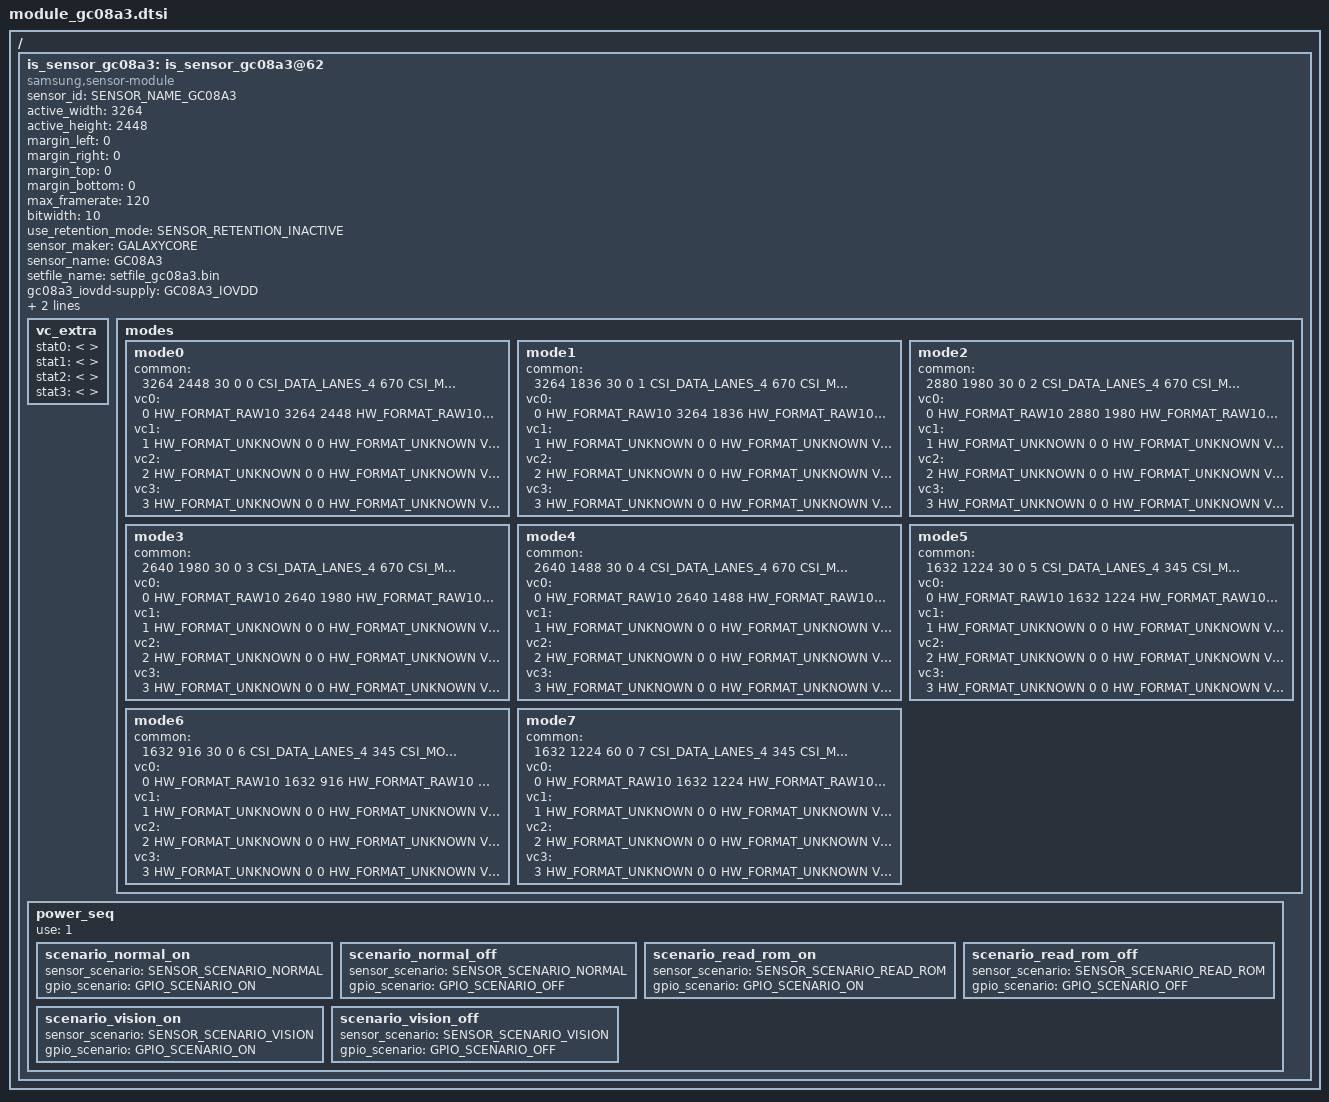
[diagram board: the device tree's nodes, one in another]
/*
 * SAMSUNG EXYNOSxxxx board camera device tree source
 *
 * Copyright (c) 2021 Samsung Electronics Co., Ltd.
 *        http://www.samsung.com
 *
 * This program is free software; you can redistribute it and/or modify
 * it under the terms of the GNU General Public License version 2 as
 * published by the Free Software Foundation.
 */

#include <dt-bindings/camera/exynos_is_dt.h>

#ifndef USE_VENDOR_PWR_PIN_NAME
#define GC08A3_IOVDD	<>
#define GC08A3_AVDD	<>
#define GC08A3_DVDD	<>
#endif

/ {
	fragment@camera {
		target-path = "/";
		__overlay__ {
			is_sensor_gc08a3: is_sensor_gc08a3@62 {
				compatible = "samsung,sensor-module";

				/* common */
				sensor_id = <SENSOR_NAME_GC08A3>;
				active_width = <3264>;
				active_height = <2448>;
				margin_left = <0>;
				margin_right = <0>;
				margin_top = <0>;
				margin_bottom = <0>;
				max_framerate = <120>;
				bitwidth = <10>;
				use_retention_mode = <SENSOR_RETENTION_INACTIVE>;
				sensor_maker = "GALAXYCORE";
				sensor_name = "GC08A3";
				setfile_name = "setfile_gc08a3.bin";

				gc08a3_iovdd-supply = GC08A3_IOVDD;
				gc08a3_avdd-supply = GC08A3_AVDD;
				gc08a3_dvdd-supply = GC08A3_DVDD;

				status = "okay";

				vc_extra {
					/* ex) statX = <stat_type, sensor_mode, max_width, max_height, max_element> */
					stat0 = </* not avaliable */>;	/* VC_BUF_DATA_TYPE_SENSOR_STAT1 */
					stat1 = </* not avaliable */>;	/* VC_BUF_DATA_TYPE_GENERAL_STAT1 */
					stat2 = </* not avaliable */>;	/* VC_BUF_DATA_TYPE_SENSOR_STAT2 */
					stat3 = </* not avaliable */>;	/* VC_BUF_DATA_TYPE_GENERAL_STAT2 */
				};

/*
 * [Mode Information]
 *
 * Reference File : GC08A3 MIPI data rate 897M official setfile V1.0.8.xlsx
 * Update Data    : 2021-10-26
 * Author         : g.lakshay
 *
 *  - Global setting
 *
 *  - Mode setting
 *  [ 0 ] 2576 x 1932(4:3)    @30,  MIPI lane: 2, MIPI data rate(Mbps/lane):  897, Mclk(Mhz): 26
 *  [ 1 ] 2560 x 1440(16:9)   @30,  MIPI lane: 2, MIPI data rate(Mbps/lane):  897, Mclk(Mhz): 26
 *  [ 2 ] 2224 x 1080(18.5:9) @30,  MIPI lane: 2, MIPI data rate(Mbps/lane):  897, Mclk(Mhz): 26
 *  [ 3 ] 2576 x 1188(19.5:9) @30,  MIPI lane: 2, MIPI data rate(Mbps/lane):  897, Mclk(Mhz): 26
 *  [ 4 ] 2576 x 1160(20:9)   @30,  MIPI lane: 2, MIPI data rate(Mbps/lane):  897, Mclk(Mhz): 26
 *  [ 5 ] 1920 x 1920(1:1)    @30,  MIPI lane: 2, MIPI data rate(Mbps/lane):  897, Mclk(Mhz): 26
 *  [ 6 ] 1280 x 960(4:3)     @30,  MIPI lane: 2, MIPI data rate(Mbps/lane):  897, Mclk(Mhz): 26
 *  [ 7 ] 1280 x 720(16:9)    @30,  MIPI lane: 2, MIPI data rate(Mbps/lane):  897, Mclk(Mhz): 26
 *  [ 8 ] 800 x 600(4:3)      @60,  MIPI lane: 2, MIPI data rate(Mbps/lane):  897, Mclk(Mhz): 26
 *  [ 9 ] 640 x 480(4:3)      @120,  MIPI lane: 2, MIPI data rate(Mbps/lane):  448, Mclk(Mhz): 26
 *
 */

				/* sensor modes */
				modes {
						/* common = <width, height, fps, settle, mode, lane, speed, interleave, lrte, pd_mode> */
						/* vcX = <map, hwformat, width, height, hwformat, type, width, height> */

					/* 0 : 3264x2448@30fps 4:3 */
					mode0 {
						common = <3264 2448 30 0 0 CSI_DATA_LANES_4 670 CSI_MODE_VC_ONLY LRTE_DISABLE PD_NONE EX_NONE>;
						vc0 = </* in */ 0 HW_FORMAT_RAW10 3264 2448	/* out */ HW_FORMAT_RAW10 VC_NOTHING 3264 2448>;
						vc1 = </* in */ 1 HW_FORMAT_UNKNOWN 0 0		/* out */ HW_FORMAT_UNKNOWN VC_NOTHING 0 0>;
						vc2 = </* in */ 2 HW_FORMAT_UNKNOWN 0 0		/* out */ HW_FORMAT_UNKNOWN VC_NOTHING 0 0>;
						vc3 = </* in */ 3 HW_FORMAT_UNKNOWN 0 0		/* out */ HW_FORMAT_UNKNOWN VC_NOTHING 0 0>;
					};
					/* 1 : 3264x1836@30fps 16:9 */
					mode1 {
						common = <3264 1836 30 0 1 CSI_DATA_LANES_4 670 CSI_MODE_VC_ONLY LRTE_DISABLE PD_NONE EX_NONE>;
						vc0 = </* in */ 0 HW_FORMAT_RAW10 3264 1836	/* out */ HW_FORMAT_RAW10 VC_NOTHING 3264 1836>;
						vc1 = </* in */ 1 HW_FORMAT_UNKNOWN 0 0		/* out */ HW_FORMAT_UNKNOWN VC_NOTHING 0 0>;
						vc2 = </* in */ 2 HW_FORMAT_UNKNOWN 0 0		/* out */ HW_FORMAT_UNKNOWN VC_NOTHING 0 0>;
						vc3 = </* in */ 3 HW_FORMAT_UNKNOWN 0 0		/* out */ HW_FORMAT_UNKNOWN VC_NOTHING 0 0>;
					};
					/* 2 : 2880x1980@30fps 16:9 */
					mode2 {
						common = <2880 1980 30 0 2 CSI_DATA_LANES_4 670 CSI_MODE_VC_ONLY LRTE_DISABLE PD_NONE EX_NONE>;
						vc0 = </* in */ 0 HW_FORMAT_RAW10 2880 1980	/* out */ HW_FORMAT_RAW10 VC_NOTHING 2880 1980>;
						vc1 = </* in */ 1 HW_FORMAT_UNKNOWN 0 0		/* out */ HW_FORMAT_UNKNOWN VC_NOTHING 0 0>;
						vc2 = </* in */ 2 HW_FORMAT_UNKNOWN 0 0		/* out */ HW_FORMAT_UNKNOWN VC_NOTHING 0 0>;
						vc3 = </* in */ 3 HW_FORMAT_UNKNOWN 0 0		/* out */ HW_FORMAT_UNKNOWN VC_NOTHING 0 0>;
					};
					/* 3 : 2640x1980@30fps 4:3 */
					mode3 {
						common = <2640 1980 30 0 3 CSI_DATA_LANES_4 670 CSI_MODE_VC_ONLY LRTE_DISABLE PD_NONE EX_NONE>;
						vc0 = </* in */ 0 HW_FORMAT_RAW10 2640 1980	/* out */ HW_FORMAT_RAW10 VC_NOTHING 2640 1980>;
						vc1 = </* in */ 1 HW_FORMAT_UNKNOWN 0 0		/* out */ HW_FORMAT_UNKNOWN VC_NOTHING 0 0>;
						vc2 = </* in */ 2 HW_FORMAT_UNKNOWN 0 0		/* out */ HW_FORMAT_UNKNOWN VC_NOTHING 0 0>;
						vc3 = </* in */ 3 HW_FORMAT_UNKNOWN 0 0		/* out */ HW_FORMAT_UNKNOWN VC_NOTHING 0 0>;
					};
					/* 4 : 2640x1488@30fps 4:3 */
					mode4 {
						common = <2640 1488 30 0 4 CSI_DATA_LANES_4 670 CSI_MODE_VC_ONLY LRTE_DISABLE PD_NONE EX_NONE>;
						vc0 = </* in */ 0 HW_FORMAT_RAW10 2640 1488	/* out */ HW_FORMAT_RAW10 VC_NOTHING 2640 1488>;
						vc1 = </* in */ 1 HW_FORMAT_UNKNOWN 0 0		/* out */ HW_FORMAT_UNKNOWN VC_NOTHING 0 0>;
						vc2 = </* in */ 2 HW_FORMAT_UNKNOWN 0 0		/* out */ HW_FORMAT_UNKNOWN VC_NOTHING 0 0>;
						vc3 = </* in */ 3 HW_FORMAT_UNKNOWN 0 0		/* out */ HW_FORMAT_UNKNOWN VC_NOTHING 0 0>;
					};
					/* 5 : 1632x1224@30fps 4:3 */
					mode5 {
						common = <1632 1224 30 0 5 CSI_DATA_LANES_4 345 CSI_MODE_VC_ONLY LRTE_DISABLE PD_NONE EX_NONE>;
						vc0 = </* in */ 0 HW_FORMAT_RAW10 1632 1224	/* out */ HW_FORMAT_RAW10 VC_NOTHING 1632 1224>;
						vc1 = </* in */ 1 HW_FORMAT_UNKNOWN 0 0		/* out */ HW_FORMAT_UNKNOWN VC_NOTHING 0 0>;
						vc2 = </* in */ 2 HW_FORMAT_UNKNOWN 0 0		/* out */ HW_FORMAT_UNKNOWN VC_NOTHING 0 0>;
						vc3 = </* in */ 3 HW_FORMAT_UNKNOWN 0 0		/* out */ HW_FORMAT_UNKNOWN VC_NOTHING 0 0>;
					};
					/* 6 : 1632x916@30fps 4:3 */
					mode6 {
						common = <1632 916 30 0 6 CSI_DATA_LANES_4 345 CSI_MODE_VC_ONLY LRTE_DISABLE PD_NONE EX_NONE>;
						vc0 = </* in */ 0 HW_FORMAT_RAW10 1632 916	/* out */ HW_FORMAT_RAW10 VC_NOTHING 1632 916>;
						vc1 = </* in */ 1 HW_FORMAT_UNKNOWN 0 0		/* out */ HW_FORMAT_UNKNOWN VC_NOTHING 0 0>;
						vc2 = </* in */ 2 HW_FORMAT_UNKNOWN 0 0		/* out */ HW_FORMAT_UNKNOWN VC_NOTHING 0 0>;
						vc3 = </* in */ 3 HW_FORMAT_UNKNOWN 0 0		/* out */ HW_FORMAT_UNKNOWN VC_NOTHING 0 0>;
					};
					/* 7 : 1632x1224@60fps 4:3 */
					mode7 {
						common = <1632 1224 60 0 7 CSI_DATA_LANES_4 345 CSI_MODE_VC_ONLY LRTE_DISABLE PD_NONE EX_NONE>;
						vc0 = </* in */ 0 HW_FORMAT_RAW10 1632 1224	/* out */ HW_FORMAT_RAW10 VC_NOTHING 1632 1224>;
						vc1 = </* in */ 1 HW_FORMAT_UNKNOWN 0 0		/* out */ HW_FORMAT_UNKNOWN VC_NOTHING 0 0>;
						vc2 = </* in */ 2 HW_FORMAT_UNKNOWN 0 0		/* out */ HW_FORMAT_UNKNOWN VC_NOTHING 0 0>;
						vc3 = </* in */ 3 HW_FORMAT_UNKNOWN 0 0		/* out */ HW_FORMAT_UNKNOWN VC_NOTHING 0 0>;
					};
				};

				power_seq {
					use = <1>;
					scenario_normal_on {
						sensor_scenario = <SENSOR_SCENARIO_NORMAL>;
						gpio_scenario = <GPIO_SCENARIO_ON>;

						/* A start node number should be over the 10 for reserved number 0~9. */
						/* pname = "name"; pin = <act value dealy voltage>; gpio = <gpx# # 0x1>; */
					};

					scenario_normal_off {
						sensor_scenario = <SENSOR_SCENARIO_NORMAL>;
						gpio_scenario = <GPIO_SCENARIO_OFF>;

						/* A start node number should be over the 10 for reserved number 0~9. */
						/* pname = "name"; pin = <act value dealy voltage>; gpio = <gpx# # 0x1>; */
					};

					scenario_read_rom_on {
						sensor_scenario = <SENSOR_SCENARIO_READ_ROM>;
						gpio_scenario = <GPIO_SCENARIO_ON>;
					};

					scenario_read_rom_off {
						sensor_scenario = <SENSOR_SCENARIO_READ_ROM>;
						gpio_scenario = <GPIO_SCENARIO_OFF>;
					};

					scenario_vision_on {
						sensor_scenario = <SENSOR_SCENARIO_VISION>;
						gpio_scenario = <GPIO_SCENARIO_ON>;

						/* A start node number should be over the 10 for reserved number 0~9. */
						/* pname = "name"; 		pin = <act value dealy voltage>;	gpio = <gpx# # 0x1>; */
					};

					scenario_vision_off {
						sensor_scenario = <SENSOR_SCENARIO_VISION>;
						gpio_scenario = <GPIO_SCENARIO_OFF>;

						/* A start node number should be over the 10 for reserved number 0~9. */
						/* pname = "name"; 		pin = <act value dealy voltage>;	gpio = <gpx# # 0x1>; */
					};
				};
			};

		}; /* end of __overlay__ */
	}; /* end of fragment */
}; /* end of root */
